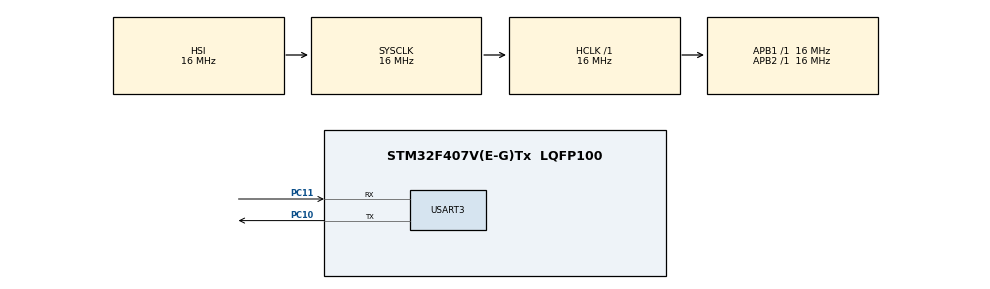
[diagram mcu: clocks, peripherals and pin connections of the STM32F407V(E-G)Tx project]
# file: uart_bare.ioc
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Mcu.Family=STM32F4
NVIC.USART3_IRQn=true\:0\:0\:false\:false\:true\:true\:true
RCC.CortexFreq_Value=16000000
PC11.Signal=USART3_RX
PC10.Signal=USART3_TX
PC10.Mode=Asynchronous
ProjectManager.StackSize=0x400
PA13.Signal=SYS_JTMS-SWDIO
ProjectManager.TargetToolchain=STM32CubeIDE
RCC.LSE_VALUE=32768
RCC.AHBFreq_Value=16000000
RCC.HSE_VALUE=25000000
PB3.Mode=Trace_Asynchronous_SW
board=custom
RCC.VCOOutputFreq_Value=192000000
RCC.APB2Freq_Value=16000000
PA14.Mode=Trace_Asynchronous_SW
PA13.Mode=Trace_Asynchronous_SW
Mcu.Name=STM32F407V(E-G)Tx
PB3.Signal=SYS_JTDO-SWO
RCC.SYSCLKFreq_VALUE=16000000
Mcu.Package=LQFP100
USART3.VirtualMode=VM_ASYNC
PA14.Signal=SYS_JTCK-SWCLK
ProjectManager.HeapSize=0x200
PC11.Mode=Asynchronous
RCC.HSI_VALUE=16000000
NVIC.PriorityGroup=NVIC_PRIORITYGROUP_4
RCC.APB1Freq_Value=16000000

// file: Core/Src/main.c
/* USER CODE BEGIN Header */
/**
  ******************************************************************************
  * @file           : main.c
  * @brief          : Main program body
  ******************************************************************************
  * @attention
  *
  * <h2><center>&copy; Copyright (c) 2024 STMicroelectronics.
  * All rights reserved.</center></h2>
  *
  * This software component is licensed by ST under BSD 3-Clause license,
  * the "License"; You may not use this file except in compliance with the
  * License. You may obtain a copy of the License at:
  *                        opensource.org/licenses/BSD-3-Clause
  *
  ******************************************************************************
  */
/* USER CODE END Header */
#include "main.h"

UART_HandleTypeDef huart3;

void SystemClock_Config(void);
static void MX_GPIO_Init(void);
static void MX_USART3_UART_Init(void);
/* USER CODE BEGIN PFP */

void USART_Send_Char(char x){
	USART3->DR = x;
	while(!(USART3->SR &(1<<6))){
	}
}

void USART_Send_Str(char *x){
	int i = 0;
	while(x[i]!='\0'){
		USART_Send_Char(x[i]);
		i+=1;
	}
}

int _write(int file, char *ptr, int len)
{
	int DataIdx;

	for (DataIdx = 0; DataIdx < len; DataIdx++)
	{
		ITM_SendChar(*ptr++);
	}
	return len;
}
/* USER CODE END PFP */

int main(void)
{
  /* USER CODE BEGIN 1 */

	RCC->AHB1ENR  = (1 << 2) ;
	RCC->APB1ENR  = (1 << 18);
	GPIOC->MODER  = (2 << 20) | (2 << 22) ;
	GPIOC->AFR[1] = (7 << 8)  | (7 << 12) ;
	USART3->CR1   = (1 << 13) | (1 << 3) | (1 << 2);
	USART3->BRR   = (7 << 0)  | (24 << 4) ;

  /* USER CODE END 1 */

  /* MCU Configuration--------------------------------------------------------*/

  /* Reset of all peripherals, Initializes the Flash interface and the Systick. */
  HAL_Init();

  /* Configure the system clock */
  SystemClock_Config();

  /* Initialize all configured peripherals */
  MX_GPIO_Init();
  MX_USART3_UART_Init();

  /* Infinite loop */
  /* USER CODE BEGIN WHILE */
  while (1)
  {
	  printf("ADITYA");
	  USART_Send_Str("ADITYA\n\r");
	  HAL_Delay(100);
    /* USER CODE END WHILE */

  }
}

void SystemClock_Config(void)
{
  RCC_OscInitTypeDef RCC_OscInitStruct = {0};
  RCC_ClkInitTypeDef RCC_ClkInitStruct = {0};

  /** Configure the main internal regulator output voltage
  */
  __HAL_RCC_PWR_CLK_ENABLE();
  __HAL_PWR_VOLTAGESCALING_CONFIG(PWR_REGULATOR_VOLTAGE_SCALE1);
  /** Initializes the RCC Oscillators according to the specified parameters
  * in the RCC_OscInitTypeDef structure.
  */
  RCC_OscInitStruct.OscillatorType = RCC_OSCILLATORTYPE_HSI;
  RCC_OscInitStruct.HSIState = RCC_HSI_ON;
  RCC_OscInitStruct.HSICalibrationValue = RCC_HSICALIBRATION_DEFAULT;
  RCC_OscInitStruct.PLL.PLLState = RCC_PLL_NONE;
  if (HAL_RCC_OscConfig(&RCC_OscInitStruct) != HAL_OK)
  {
    Error_Handler();
  }
  /** Initializes the CPU, AHB and APB buses clocks
  */
  RCC_ClkInitStruct.ClockType = RCC_CLOCKTYPE_HCLK|RCC_CLOCKTYPE_SYSCLK
                              |RCC_CLOCKTYPE_PCLK1|RCC_CLOCKTYPE_PCLK2;
  RCC_ClkInitStruct.SYSCLKSource = RCC_SYSCLKSOURCE_HSI;
  RCC_ClkInitStruct.AHBCLKDivider = RCC_SYSCLK_DIV1;
  RCC_ClkInitStruct.APB1CLKDivider = RCC_HCLK_DIV1;
  RCC_ClkInitStruct.APB2CLKDivider = RCC_HCLK_DIV1;

  if (HAL_RCC_ClockConfig(&RCC_ClkInitStruct, FLASH_LATENCY_0) != HAL_OK)
  {
    Error_Handler();
  }
}

static void MX_USART3_UART_Init(void)
{

  huart3.Instance = USART3;
  huart3.Init.BaudRate = 115200;
  huart3.Init.WordLength = UART_WORDLENGTH_8B;
  huart3.Init.StopBits = UART_STOPBITS_1;
  huart3.Init.Parity = UART_PARITY_NONE;
  huart3.Init.Mode = UART_MODE_TX_RX;
  huart3.Init.HwFlowCtl = UART_HWCONTROL_NONE;
  huart3.Init.OverSampling = UART_OVERSAMPLING_16;
  if (HAL_UART_Init(&huart3) != HAL_OK)
  {
    Error_Handler();
  }

}

static void MX_GPIO_Init(void)
{

  /* GPIO Ports Clock Enable */
  __HAL_RCC_GPIOA_CLK_ENABLE();
  __HAL_RCC_GPIOC_CLK_ENABLE();
  __HAL_RCC_GPIOB_CLK_ENABLE();

}

void Error_Handler(void)
{
  __disable_irq();
  while (1)
  {
  }
}

/************************ (C) COPYRIGHT STMicroelectronics *****END OF FILE****/
